AUTOSAR XML (schema 4-2-2)
package /Components
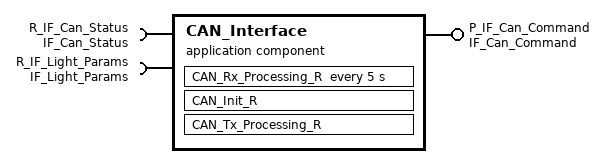
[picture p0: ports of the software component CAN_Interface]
  application sw component type CAN_Interface
    provide port P_IF_Can_Command: provided-interface=IF_Can_Command
    require port R_IF_Can_Status: required-interface=IF_Can_Status
    require port R_IF_Light_Params: required-interface=IF_Light_Params
    behavior CAN_Interface_InternalBehavior
      data received event CAN_Status_Update_Received: start-on-event=CAN_Tx_Processing_R
      init event CAN_Init_Event: start-on-event=CAN_Init_R
      timing event CAN_Poll_5ms: start-on-event=CAN_Rx_Processing_R, period=5
      runnable CAN_Init_R
        4 x parameter access:
          ParamAccess_PwmMaxDuty: accessed-parameter=R_IF_Light_Params.pwm_max_duty
          ParamAccess_PwmMinDuty: accessed-parameter=R_IF_Light_Params.pwm_min_duty
          ParamAccess_FaultCurrentThreshold: accessed-parameter=R_IF_Light_Params.fault_current_threshold
          ParamAccess_RetryCount: accessed-parameter=R_IF_Light_Params.retry_count
      runnable CAN_Rx_Processing_R: minimum-start-interval=5
        data-send-points:
          7 x access:
            Send_Headlamp_On_Cmd: accessed-variable=P_IF_Can_Command.headlamp_on_cmd
            Send_TailLamp_On_Cmd: accessed-variable=P_IF_Can_Command.tail_lamp_on_cmd
            Send_LeftTurn_Cmd: accessed-variable=P_IF_Can_Command.left_turn_cmd
            Send_RightTurn_Cmd: accessed-variable=P_IF_Can_Command.right_turn_cmd
            Send_Headlamp_Brightness_Cmd: accessed-variable=P_IF_Can_Command.headlamp_brightness_cmd
            Send_Tail_Brightness_Cmd: accessed-variable=P_IF_Can_Command.tail_brightness_cmd
            Send_Turn_Brightness_Cmd: accessed-variable=P_IF_Can_Command.turn_brightness_cmd
      runnable CAN_Tx_Processing_R: minimum-start-interval=5
        data-receive-point-by-arguments:
          5 x access:
            Recv_Headlamp_Status: accessed-variable=R_IF_Can_Status.headlamp_status
            Recv_TailLamp_Status: accessed-variable=R_IF_Can_Status.tail_lamp_status
            Recv_LeftTurn_Status: accessed-variable=R_IF_Can_Status.left_turn_status
            Recv_RightTurn_Status: accessed-variable=R_IF_Can_Status.right_turn_status
            Recv_Fault_Code: accessed-variable=R_IF_Can_Status.fault_code
